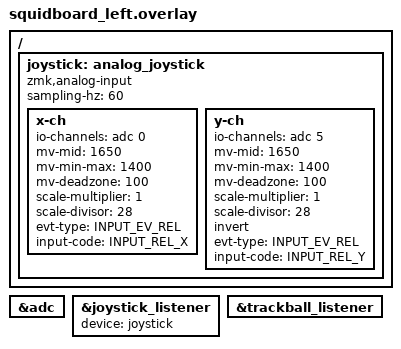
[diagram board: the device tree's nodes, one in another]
#include <zephyr/dt-bindings/input/input-event-codes.h>

#include "squidboard.dtsi"

&adc {
    status = "okay";
};

/ {
    joystick: analog_joystick {
        compatible = "zmk,analog-input";
        sampling-hz = <60>;

        x-ch {
            // nice!nano D19/A1 is nRF52840 AIN0.
            io-channels = <&adc 0>;
            mv-mid = <1650>;
            mv-min-max = <1400>;
            mv-deadzone = <100>;
            scale-multiplier = <1>;
            scale-divisor = <28>;
            evt-type = <INPUT_EV_REL>;
            input-code = <INPUT_REL_X>;
        };

        y-ch {
            // nice!nano D20/A2 is nRF52840 AIN5.
            io-channels = <&adc 5>;
            mv-mid = <1650>;
            mv-min-max = <1400>;
            mv-deadzone = <100>;
            scale-multiplier = <1>;
            scale-divisor = <28>;
            invert;
            evt-type = <INPUT_EV_REL>;
            input-code = <INPUT_REL_Y>;
        };
    };
};

&joystick_listener {
    device = <&joystick>;
    status = "okay";
};

&trackball_listener {
    status = "okay";
};
